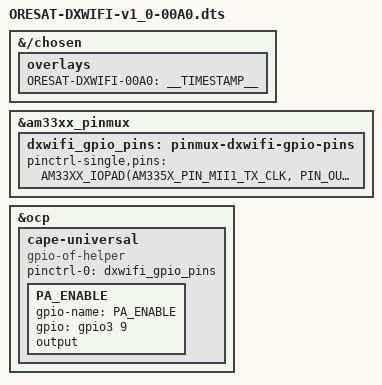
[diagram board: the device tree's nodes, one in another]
/* OreSat DxWiFi overlay */

/dts-v1/;
/plugin/;

#include "am33xx.h"

&{/chosen} {
  overlays {
    ORESAT-DXWIFI-00A0 = __TIMESTAMP__;
  };
};

/ {
  fragment@0 {
    target = <&am33xx_pinmux>;
    __overlay__ {
      dxwifi_gpio_pins: pinmux-dxwifi-gpio-pins {
        pinctrl-single,pins = <
          AM33XX_IOPAD(AM335X_PIN_MII1_TX_CLK, PIN_OUTPUT | MUX_MODE7) /* gpio3_9 */
        >;
      };
    };
  };

  fragment@1 {
    target = <&ocp>;
    __overlay__ {
      cape-universal {
        compatible = "gpio-of-helper";
        status = "okay";
        pinctrl-names = "default";
        pinctrl-0 = <&dxwifi_gpio_pins>;

        PA_ENABLE {
          gpio-name = "PA_ENABLE";
          gpio = <&gpio3 9 0>; /* AM335X_PIN_MII1_TX_CLK */
          output;
        };
      };
    };
  };
};
